# SAM9X60D1G_SOM register map
Vendor: Microchip Technology; Series: SAM9X6; File version: 0
Registers are 32-bit, read-write, reset 0x0 unless marked. A register's access mark holds for its fields unless they carry their own. Offsets are from the block's base; [hi:lo] are bit positions; {n}, {i} and the like mark numbered series; 'fields as' and 'values as' point back to an identical list.

## LCDC — LCD Controller
Base 0xF8038000
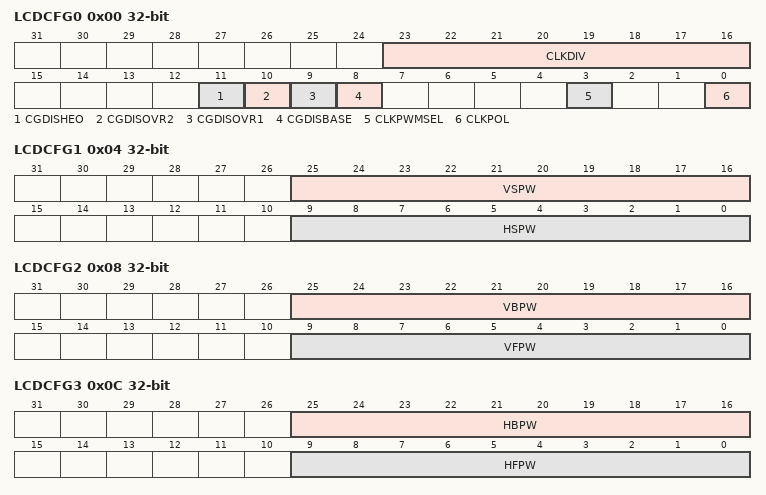
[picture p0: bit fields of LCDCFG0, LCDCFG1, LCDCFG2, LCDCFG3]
0x00 LCDCFG0 — LCD Controller Configuration Register 0
  [23:16] CLKDIV — LCD Controller Clock Divider
  [11] CGDISHEO — Clock Gating Disable Control for the High-End Overlay
  [10] CGDISOVR2 — Clock Gating Disable Control for the Overlay 2 Layer
  [9] CGDISOVR1 — Clock Gating Disable Control for the Overlay 1 Layer
  [8] CGDISBASE — Clock Gating Disable Control for the Base Layer
  [3] CLKPWMSEL — LCD Controller PWM Clock Source Selection
  [0] CLKPOL — LCD Controller Clock Polarity
0x04 LCDCFG1 — LCD Controller Configuration Register 1
  [25:16] VSPW — Vertical Synchronization Pulse Width
  [9:0] HSPW — Horizontal Synchronization Pulse Width
0x08 LCDCFG2 — LCD Controller Configuration Register 2
  [25:16] VBPW — Vertical Back Porch Width
  [9:0] VFPW — Vertical Front Porch Width
0x0C LCDCFG3 — LCD Controller Configuration Register 3
  [25:16] HBPW — Horizontal Back Porch Width
  [9:0] HFPW — Horizontal Front Porch Width
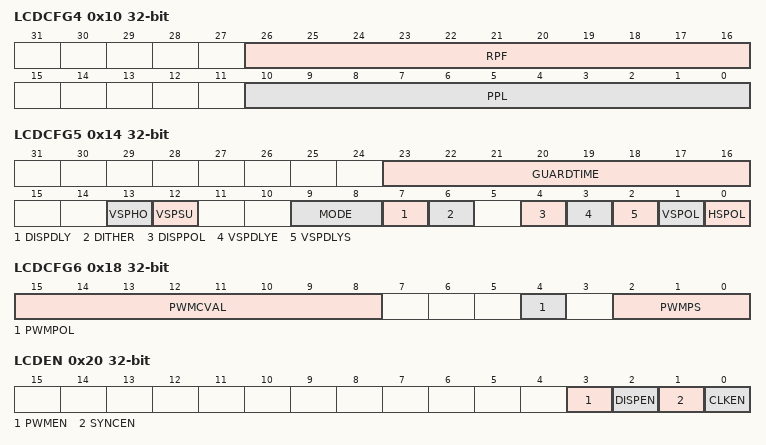
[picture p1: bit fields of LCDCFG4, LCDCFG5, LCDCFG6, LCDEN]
0x10 LCDCFG4 — LCD Controller Configuration Register 4
  [26:16] RPF — Number of Active Row Per Frame
  [10:0] PPL — Number of Pixels Per Line
0x14 LCDCFG5 — LCD Controller Configuration Register 5
  [23:16] GUARDTIME — LCD DISPLAY Guard Time
  [13] VSPHO — LCD Controller Vertical synchronization Pulse Hold Configuration
  [12] VSPSU — LCD Controller Vertical synchronization Pulse Setup Configuration
  [9:8] MODE — LCD Controller Output Mode
    0=OUTPUT_12BPP (LCD Output mode is set to 12 bits per pixel); 1=OUTPUT_16BPP (LCD Output mode is set to 16 bits per pixel); 2=OUTPUT_18BPP (LCD Output mode is set to 18 bits per pixel); 3=OUTPUT_24BPP (LCD Output mode is set to 24 bits per pixel)
  [7] DISPDLY — LCD Controller Display Power Signal Synchronization
  [6] DITHER — LCD Controller Dithering
  [4] DISPPOL — Display Signal Polarity
  [3] VSPDLYE — Vertical Synchronization Pulse End
  [2] VSPDLYS — Vertical Synchronization Pulse Start
  [1] VSPOL — Vertical Synchronization Pulse Polarity
  [0] HSPOL — Horizontal Synchronization Pulse Polarity
0x18 LCDCFG6 — LCD Controller Configuration Register 6
  [15:8] PWMCVAL — LCD Controller PWM Compare Value
  [4] PWMPOL — LCD Controller PWM Signal Polarity
  [2:0] PWMPS — PWM Clock Prescaler
    0=DIV_1 (The counter advances at a rate of fCOUNTER = fPWM_SELECTED_CLOCK); 1=DIV_2 (The counter advances at a rate of fCOUNTER = fPWM_SELECTED_CLOCK/2); 2=DIV_4 (The counter advances at a rate of fCOUNTER = fPWM_SELECTED_CLOCK/4); 3=DIV_8 (The counter advances at a rate of fCOUNTER = fPWM_SELECTED_CLOCK/8); 4=DIV_16 (The counter advances at a rate of fCOUNTER = fPWM_SELECTED_CLOCK/16); 5=DIV_32 (The counter advances at a of rate fCOUNTER = fPWM_SELECTED_CLOCK/32); 6=DIV_64 (The counter advances at a of rate fCOUNTER = fPWM_SELECTED_CLOCK/64)
0x1C LCDCFG7 — LCD Controller Configuration Register 7
  [10:0] ROW — Row Identifier For Row Interrupt Signal
0x20 LCDEN wo — LCD Controller Enable Register
  [3] PWMEN — LCD Controller Pulse Width Modulation Enable
  [2] DISPEN — LCD Controller DISP Signal Enable
  [1] SYNCEN — LCD Controller Horizontal and Vertical Synchronization Enable
  [0] CLKEN — LCD Controller Pixel Clock Enable
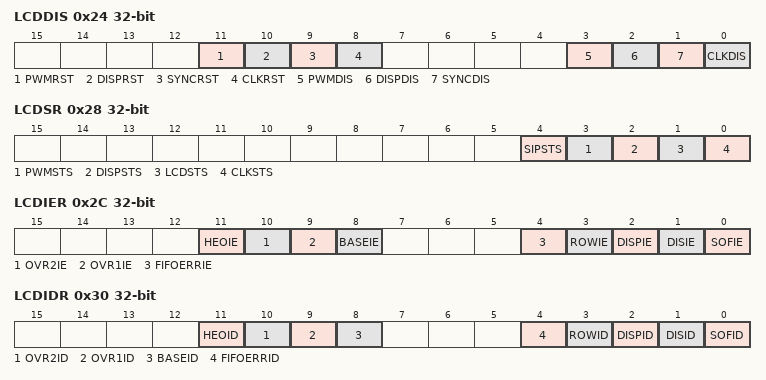
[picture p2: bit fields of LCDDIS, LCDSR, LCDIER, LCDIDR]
0x24 LCDDIS wo — LCD Controller Disable Register
  [11] PWMRST — LCD Controller PWM Reset
  [10] DISPRST — LCD Controller DISP Signal Reset
  [9] SYNCRST — LCD Controller Horizontal and Vertical Synchronization Reset
  [8] CLKRST — LCD Controller Clock Reset
  [3] PWMDIS — LCD Controller Pulse Width Modulation Disable
  [2] DISPDIS — LCD Controller DISP Signal Disable
  [1] SYNCDIS — LCD Controller Horizontal and Vertical Synchronization Disable
  [0] CLKDIS — LCD Controller Pixel Clock Disable
0x28 LCDSR ro — LCD Controller Status Register
  [4] SIPSTS — Synchronization In Progress
  [3] PWMSTS — LCD Controller PWM Signal Status
  [2] DISPSTS — LCD Controller DISP Signal Status
  [1] LCDSTS — LCD Controller Synchronization status
  [0] CLKSTS — Clock Status
0x2C LCDIER wo — LCD Controller Interrupt Enable Register
  [11] HEOIE — High-End Overlay Interrupt Enable
  [10] OVR2IE — Overlay 2 Interrupt Enable
  [9] OVR1IE — Overlay 1 Interrupt Enable
  [8] BASEIE — Base Layer Interrupt Enable
  [4] FIFOERRIE — Output FIFO Error Interrupt Enable
  [3] ROWIE — Row Interrupt Enable
  [2] DISPIE — Powerup/Powerdown Sequence Terminated Interrupt Enable
  [1] DISIE — LCD Disable Interrupt Enable
  [0] SOFIE — Start of Frame Interrupt Enable
0x30 LCDIDR wo — LCD Controller Interrupt Disable Register
  [11] HEOID — High-End Overlay Interrupt Disable
  [10] OVR2ID — Overlay 2 Interrupt Disable
  [9] OVR1ID — Overlay 1 Interrupt Disable
  [8] BASEID — Base Layer Interrupt Disable
  [4] FIFOERRID — Output FIFO Error Interrupt Disable
  [3] ROWID — Row Interrupt Disable
  [2] DISPID — Powerup/Powerdown Sequence Terminated Interrupt Disable
  [1] DISID — LCD Disable Interrupt Disable
  [0] SOFID — Start of Frame Interrupt Disable
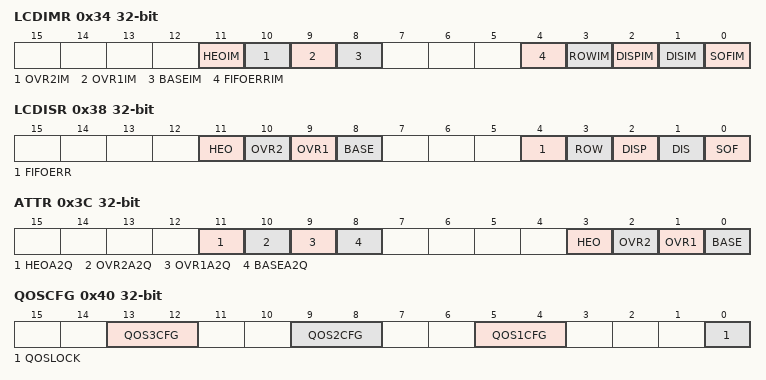
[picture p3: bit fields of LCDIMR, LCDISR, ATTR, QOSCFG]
0x34 LCDIMR ro — LCD Controller Interrupt Mask Register
  [11] HEOIM — High-End Overlay Interrupt Mask
  [10] OVR2IM — Overlay 2 Interrupt Mask
  [9] OVR1IM — Overlay 1 Interrupt Mask
  [8] BASEIM — Base Layer Interrupt Mask
  [4] FIFOERRIM — Output FIFO Error Interrupt Mask
  [3] ROWIM — Row Interrupt Mask
  [2] DISPIM — Powerup/Powerdown Sequence Terminated Interrupt Mask
  [1] DISIM — LCD Disable Interrupt Mask
  [0] SOFIM — Start of Frame Interrupt Mask
0x38 LCDISR ro — LCD Controller Interrupt Status Register
  [11] HEO — High-End Overlay Raw Interrupt Status
  [10] OVR2 — Overlay 2 Raw Interrupt Status
  [9] OVR1 — Overlay 1 Raw Interrupt Status
  [8] BASE — Base Layer Raw Interrupt Status
  [4] FIFOERR — Output FIFO Error
  [3] ROW — Row Interrupt Status
  [2] DISP — Powerup/Powerdown Sequence Terminated Interrupt Status
  [1] DIS — LCD Disable Interrupt Status
  [0] SOF — Start of Frame Interrupt Status
0x3C ATTR wo — LCD Controller Attribute Register
  [11] HEOA2Q — High-End Overlay Update Add To Queue
  [10] OVR2A2Q — Overlay 2 Update Add to Queue
  [9] OVR1A2Q — Overlay 1 Update Add To Queue
  [8] BASEA2Q — Base Layer Update Add To Queue
  [3] HEO — High-End Overlay Update Attribute
  [2] OVR2 — Overlay 2 Update Attribute
  [1] OVR1 — Overlay 1 Update Attribute
  [0] BASE — Base Layer Update Attribute
0x40 QOSCFG — LCD Controller QoS Configuration Register
  [13:12] QOS3CFG — Quality Of Service for 2 to 3 Transition
  [9:8] QOS2CFG — Quality Of Service for 1 to 2 Transition
  [5:4] QOS1CFG — Quality Of Service for 0 to 1 Transition
  [0] QOSLOCK — Quality Of Service Lock
{0x40+4i} QOS{i}M ro (i=1..3) — LCD Controller QoS {i} Metrics Register
  [19:0] MET{i} — Metrics QoS {i}
0x50 QOSMIN ro — LCD Controller QoS Min FIFO Level Register
  [8:0] LEVEL — Minimum FIFO Level
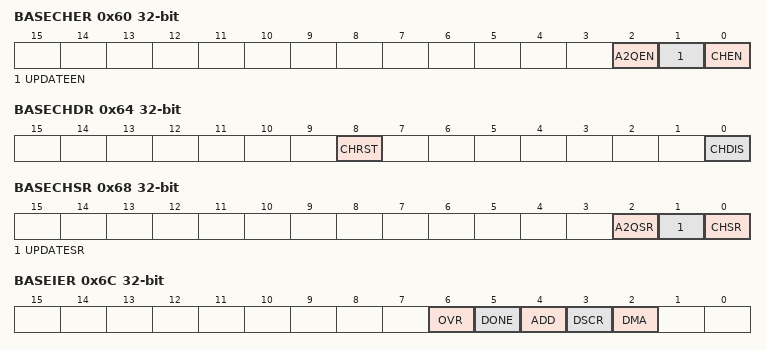
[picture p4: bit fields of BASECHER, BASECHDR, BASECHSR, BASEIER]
0x60 BASECHER wo — Base Layer Channel Enable Register
  [2] A2QEN — Add To Queue Enable
  [1] UPDATEEN — Update Overlay Attributes Enable
  [0] CHEN — Channel Enable
0x64 BASECHDR wo — Base Layer Channel Disable Register
  [8] CHRST — Channel Reset
  [0] CHDIS — Channel Disable
0x68 BASECHSR ro — Base Layer Channel Status Register
  [2] A2QSR — Add To Queue Status
  [1] UPDATESR — Update Overlay Attributes In Progress Status
  [0] CHSR — Channel Status
0x6C BASEIER wo — Base Layer Interrupt Enable Register
  [6] OVR — Overflow Interrupt Enable
  [5] DONE — End of List Interrupt Enable
  [4] ADD — Head Descriptor Loaded Interrupt Enable
  [3] DSCR — Descriptor Loaded Interrupt Enable
  [2] DMA — End of DMA Transfer Interrupt Enable
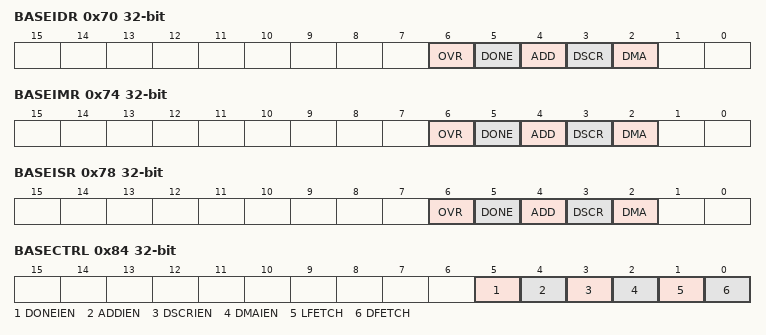
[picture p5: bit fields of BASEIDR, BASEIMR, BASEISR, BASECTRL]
0x70 BASEIDR wo — Base Layer Interrupt Disabled Register
  [6] OVR — Overflow Interrupt Disable
  [5] DONE — End of List Interrupt Disable
  [4] ADD — Head Descriptor Loaded Interrupt Disable
  [3] DSCR — Descriptor Loaded Interrupt Disable
  [2] DMA — End of DMA Transfer Interrupt Disable
0x74 BASEIMR ro — Base Layer Interrupt Mask Register
  [6] OVR — Overflow Interrupt Mask
  [5] DONE — End of List Interrupt Mask
  [4] ADD — Head Descriptor Loaded Interrupt Mask
  [3] DSCR — Descriptor Loaded Interrupt Mask
  [2] DMA — End of DMA Transfer Interrupt Mask
0x78 BASEISR ro — Base Layer Interrupt Status Register
  [6] OVR — Overflow Detected
  [5] DONE — End of List Detected
  [4] ADD — Head Descriptor Loaded
  [3] DSCR — DMA Descriptor Loaded
  [2] DMA — End of DMA Transfer
0x7C BASEHEAD — Base DMA Head Register
  [31:2] HEAD — DMA Head Pointer
0x80 BASEADDR — Base DMA Address Register
  [31:0] ADDR — DMA Transfer Start Address
0x84 BASECTRL — Base DMA Control Register
  [5] DONEIEN — End of List Interrupt Enable
  [4] ADDIEN — Add Head Descriptor to Queue Interrupt Enable
  [3] DSCRIEN — Descriptor Loaded Interrupt Enable
  [2] DMAIEN — End of DMA Transfer Interrupt Enable
  [1] LFETCH — Lookup Table Fetch Enable
  [0] DFETCH — Transfer Descriptor Fetch Enable
0x88 BASENEXT — Base DMA Next Register
  [31:0] NEXT — DMA Descriptor Next Address
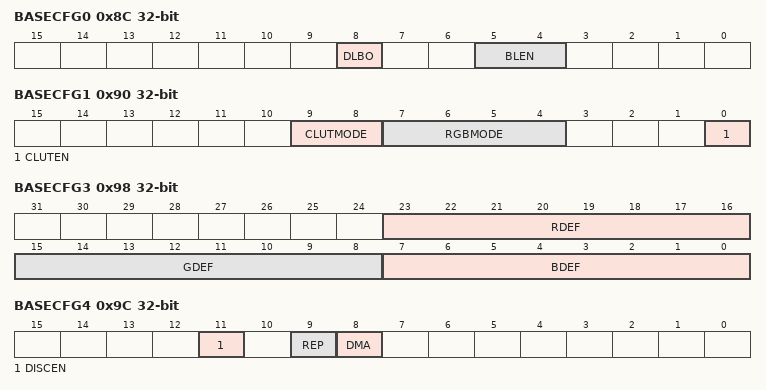
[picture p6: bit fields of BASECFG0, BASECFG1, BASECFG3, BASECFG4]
0x8C BASECFG0 — Base Layer Configuration Register 0
  [8] DLBO — defined length Burst Only For Channel Bus Transaction
  [5:4] BLEN — System Bus Burst Length
    0=AHB_SINGLE (System bus access is started as soon as there is enough space in the FIFO to store one data. SINGLE, INCR, INCR4, INCR8 and INCR16 bursts are used. INCR is used for a burst of 2 and 3 beats.); 1=AHB_INCR4 (System bus access is started as soon as there is enough space in the FIFO to store a total amount of 4 data. A system bus INCR4 Burst is used. SINGLE, INCR and INCR4 bursts are used. INCR is used for a burst of 2 and 3 beats.); 2=AHB_INCR8 (System bus access is started as soon as there is enough space in the FIFO to store a total amount of 8 data. A system bus INCR8 Burst is used. SINGLE, INCR, INCR4 and INCR8 bursts are used. INCR is used for a burst of 2 and 3 beats.); 3=AHB_INCR16 (System bus access is started as soon as there is enough space in the FIFO to store a total amount of 16 data. A system bus INCR16 Burst is used. SINGLE, INCR, INCR4, INCR8 and INCR16 bursts are used. INCR is used for a burst of 2 and 3 beats.)
0x90 BASECFG1 — Base Layer Configuration Register 1
  [9:8] CLUTMODE — Color Lookup Table Mode Input Selection
    0=CLUT_1BPP (Color Lookup Table mode set to 1 bit per pixel); 1=CLUT_2BPP (Color Lookup Table mode set to 2 bits per pixel); 2=CLUT_4BPP (Color Lookup Table mode set to 4 bits per pixel); 3=CLUT_8BPP (Color Lookup Table mode set to 8 bits per pixel)
  [7:4] RGBMODE — RGB Mode Input Selection
    0=_12BPP_RGB_444; 1=_16BPP_ARGB_4444; 2=_16BPP_RGBA_4444; 3=_16BPP_RGB_565; 4=_16BPP_TRGB_1555; 5=_18BPP_RGB_666; 6=_18BPP_RGB_666PACKED; 7=_19BPP_TRGB_1666; 8=_19BPP_TRGB_PACKED (19 bpp TRGB 1666 PACKED); 9=_24BPP_RGB_888; 10=_24BPP_RGB_888_PACKED; 11=_25BPP_TRGB_1888; 12=_32BPP_ARGB_8888; 13=_32BPP_RGBA_8888
  [0] CLUTEN — Color Lookup Table Mode Enable
0x94 BASECFG2 — Base Layer Configuration Register 2
  [31:0] XSTRIDE — Horizontal Stride
0x98 BASECFG3 — Base Layer Configuration Register 3
  [23:16] RDEF — Red Default
  [15:8] GDEF — Green Default
  [7:0] BDEF — Blue Default
0x9C BASECFG4 — Base Layer Configuration Register 4
  [11] DISCEN — Discard Area Enable
  [9] REP — Use Replication logic to expand RGB color to 24 bits
  [8] DMA — Use DMA Data Path
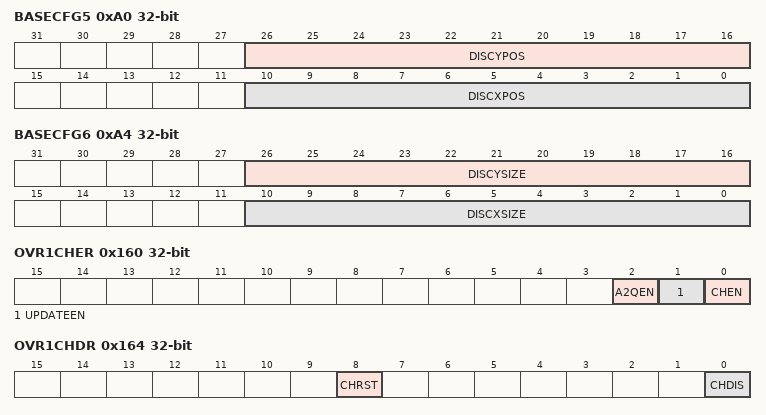
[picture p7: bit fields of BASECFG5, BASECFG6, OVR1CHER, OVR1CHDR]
0xA0 BASECFG5 — Base Layer Configuration Register 5
  [26:16] DISCYPOS — Discard Area Vertical Coordinate
  [10:0] DISCXPOS — Discard Area Horizontal Coordinate
0xA4 BASECFG6 — Base Layer Configuration Register 6
  [26:16] DISCYSIZE — Discard Area Vertical Size
  [10:0] DISCXSIZE — Discard Area Horizontal Size
0x160 OVR1CHER wo — Overlay 1 Channel Enable Register
  fields as BASECHER
0x164 OVR1CHDR wo — Overlay 1 Channel Disable Register
  [8] CHRST — Channel Reset
  [0] CHDIS — Channel Disable
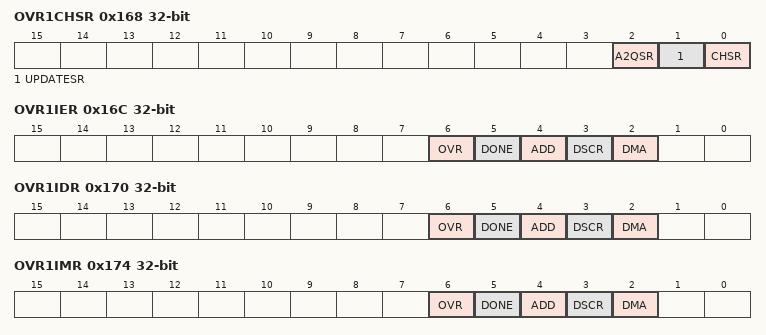
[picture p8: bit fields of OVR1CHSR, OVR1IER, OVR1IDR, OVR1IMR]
0x168 OVR1CHSR ro — Overlay 1 Channel Status Register
  fields as BASECHSR
0x16C OVR1IER wo — Overlay 1 Interrupt Enable Register
  fields as BASEIER
0x170 OVR1IDR wo — Overlay 1 Interrupt Disable Register
  fields as BASEIDR
0x174 OVR1IMR ro — Overlay 1 Interrupt Mask Register
  fields as BASEIMR
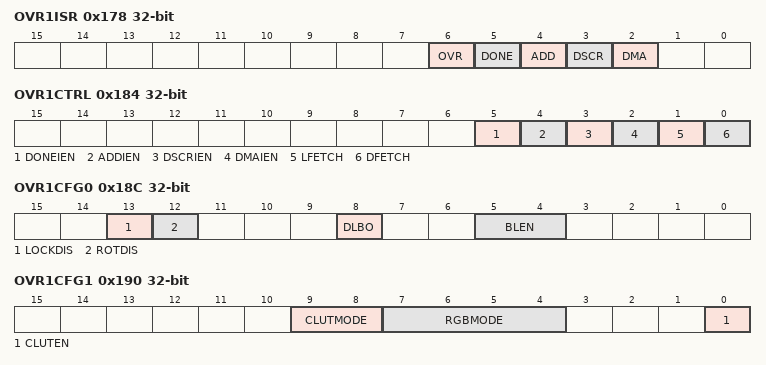
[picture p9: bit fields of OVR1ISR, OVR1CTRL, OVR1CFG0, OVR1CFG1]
0x178 OVR1ISR ro — Overlay 1 Interrupt Status Register
  fields as BASEISR
0x17C OVR1HEAD — Overlay 1 DMA Head Register
  [31:2] HEAD — DMA Head Pointer
0x180 OVR1ADDR — Overlay 1 DMA Address Register
  [31:0] ADDR — DMA Transfer Overlay 1 Address
0x184 OVR1CTRL — Overlay 1 DMA Control Register
  fields as BASECTRL
0x188 OVR1NEXT — Overlay 1 DMA Next Register
  [31:0] NEXT — DMA Descriptor Next Address
0x18C OVR1CFG0 — Overlay 1 Configuration Register 0
  [13] LOCKDIS — Hardware Rotation Lock Disable
  [12] ROTDIS — Hardware Rotation Optimization Disable
  [8] DLBO — defined length Burst Only for Channel Bus Transaction
  [5:4] BLEN — System Bus Burst Length
    0=AHB_BLEN_SINGLE (System bus access is started as soon as there is enough space in the FIFO to store one data. SINGLE, INCR, INCR4, INCR8 and INCR16 bursts are used. INCR is used for a burst of 2 and 3 beats.); 1=AHB_BLEN_INCR4 (System bus access is started as soon as there is enough space in the FIFO to store a total amount of 4 data. A system bus INCR4 Burst is used. SINGLE, INCR and INCR4 bursts are used. INCR is used for a burst of 2 and 3 beats.); 2=AHB_BLEN_INCR8 (System bus access is started as soon as there is enough space in the FIFO to store a total amount of 8 data. A system bus INCR8 Burst is used. SINGLE, INCR, INCR4 and INCR8 bursts are used. INCR is used for a burst of 2 and 3 beats.); 3=AHB_BLEN_INCR16 (System bus access is started as soon as there is enough space in the FIFO to store a total amount of 16 data. A system bus INCR16 Burst is used. SINGLE, INCR, INCR4, INCR8 and INCR16 bursts are used. INCR is used for a burst of 2 and 3 beats.)
0x190 OVR1CFG1 — Overlay 1 Configuration Register 1
  fields as BASECFG1
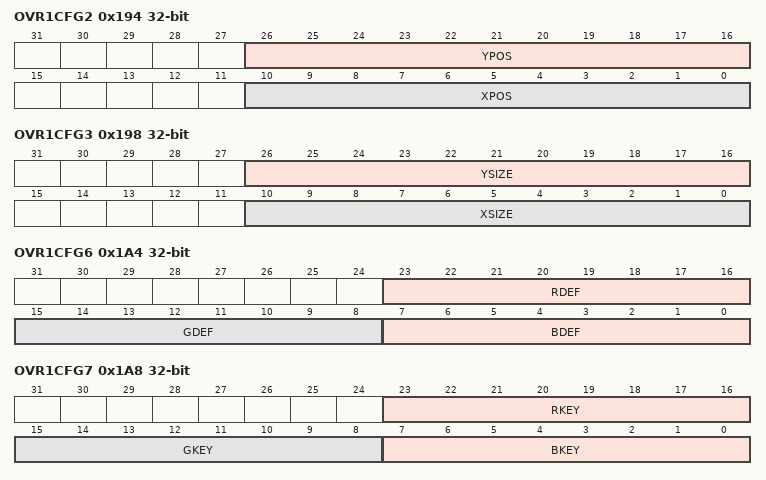
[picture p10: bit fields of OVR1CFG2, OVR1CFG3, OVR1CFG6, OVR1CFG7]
0x194 OVR1CFG2 — Overlay 1 Configuration Register 2
  [26:16] YPOS — Vertical Window Position
  [10:0] XPOS — Horizontal Window Position
0x198 OVR1CFG3 — Overlay 1 Configuration Register 3
  [26:16] YSIZE — Vertical Window Size
  [10:0] XSIZE — Horizontal Window Size
0x19C OVR1CFG4 — Overlay 1 Configuration Register 4
  [31:0] XSTRIDE — Horizontal Stride
0x1A0 OVR1CFG5 — Overlay 1 Configuration Register 5
  [31:0] PSTRIDE — Pixel Stride
0x1A4 OVR1CFG6 — Overlay 1 Configuration Register 6
  fields as BASECFG3
0x1A8 OVR1CFG7 — Overlay 1 Configuration Register 7
  [23:16] RKEY — Red Color Component Chroma Key
  [15:8] GKEY — Green Color Component Chroma Key
  [7:0] BKEY — Blue Color Component Chroma Key
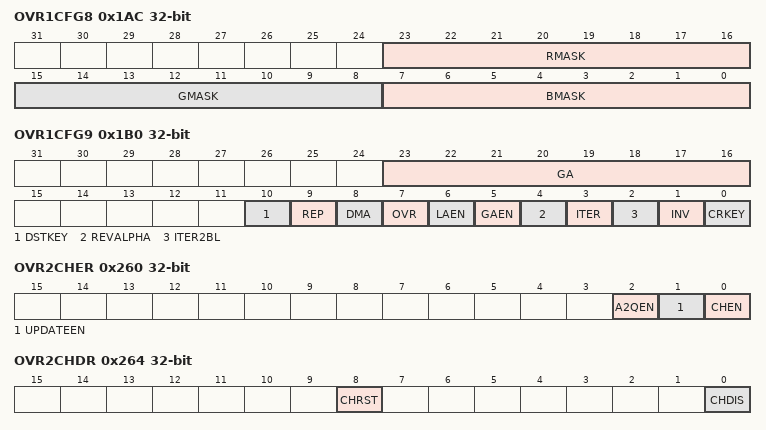
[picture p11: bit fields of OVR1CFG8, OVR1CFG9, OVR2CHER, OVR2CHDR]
0x1AC OVR1CFG8 — Overlay 1 Configuration Register 8
  [23:16] RMASK — Red Color Component Chroma Key Mask
  [15:8] GMASK — Green Color Component Chroma Key Mask
  [7:0] BMASK — Blue Color Component Chroma Key Mask
0x1B0 OVR1CFG9 — Overlay 1 Configuration Register 9
  [23:16] GA — Blender Global Alpha
  [10] DSTKEY — Destination Chroma Keying
  [9] REP — Use Replication logic to expand RGB color to 24 bits
  [8] DMA — Blender DMA Layer Enable
  [7] OVR — Blender Overlay Layer Enable
  [6] LAEN — Blender Local Alpha Enable
  [5] GAEN — Blender Global Alpha Enable
  [4] REVALPHA — Blender Reverse Alpha
  [3] ITER — Blender Use Iterated Color
  [2] ITER2BL — Blender Iterated Color Enable
  [1] INV — Blender Inverted Blender Output Enable
  [0] CRKEY — Blender Chroma Key Enable
0x260 OVR2CHER wo — Overlay 2 Channel Enable Register
  fields as BASECHER
0x264 OVR2CHDR wo — Overlay 2 Channel Disable Register
  [8] CHRST — Channel Reset
  [0] CHDIS — Channel Disable
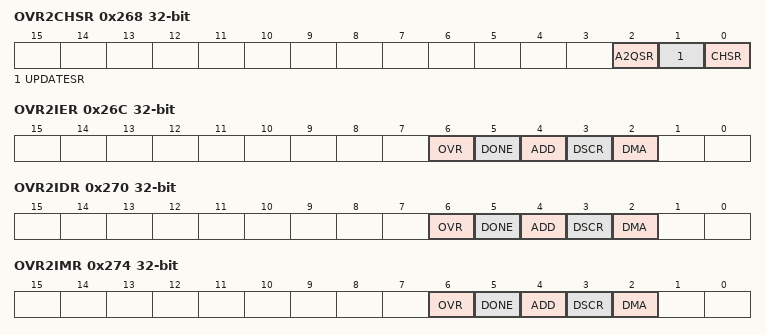
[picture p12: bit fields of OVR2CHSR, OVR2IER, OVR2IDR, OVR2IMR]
0x268 OVR2CHSR ro — Overlay 2 Channel Status Register
  fields as BASECHSR
0x26C OVR2IER wo — Overlay 2 Interrupt Enable Register
  fields as BASEIER
0x270 OVR2IDR wo — Overlay 2 Interrupt Disable Register
  fields as BASEIDR
0x274 OVR2IMR ro — Overlay 2 Interrupt Mask Register
  fields as BASEIMR
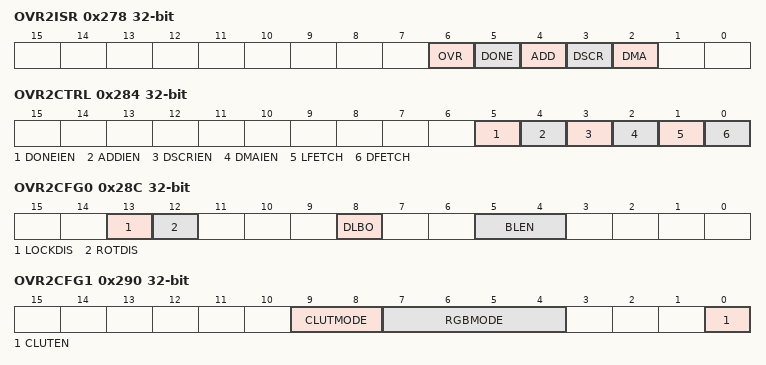
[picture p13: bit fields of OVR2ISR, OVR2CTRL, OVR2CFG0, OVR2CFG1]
0x278 OVR2ISR ro — Overlay 2 Interrupt Status Register
  fields as BASEISR
0x27C OVR2HEAD — Overlay 2 DMA Head Register
  [31:2] HEAD — DMA Head Pointer
0x280 OVR2ADDR — Overlay 2 DMA Address Register
  [31:0] ADDR — DMA Transfer Overlay 2 Address
0x284 OVR2CTRL — Overlay 2 DMA Control Register
  fields as BASECTRL
0x288 OVR2NEXT — Overlay 2 DMA Next Register
  [31:0] NEXT — DMA Descriptor Next Address
0x28C OVR2CFG0 — Overlay 2 Configuration Register 0
  [13] LOCKDIS — Hardware Rotation Lock Disable
  [12] ROTDIS — Hardware Rotation Optimization Disable
  [8] DLBO — Defined Length Burst Only For Channel Bus Transaction
  [5:4] BLEN — System Bus Burst Length
    values as BASECFG0.BLEN
0x290 OVR2CFG1 — Overlay 2 Configuration Register 1
  fields as BASECFG1
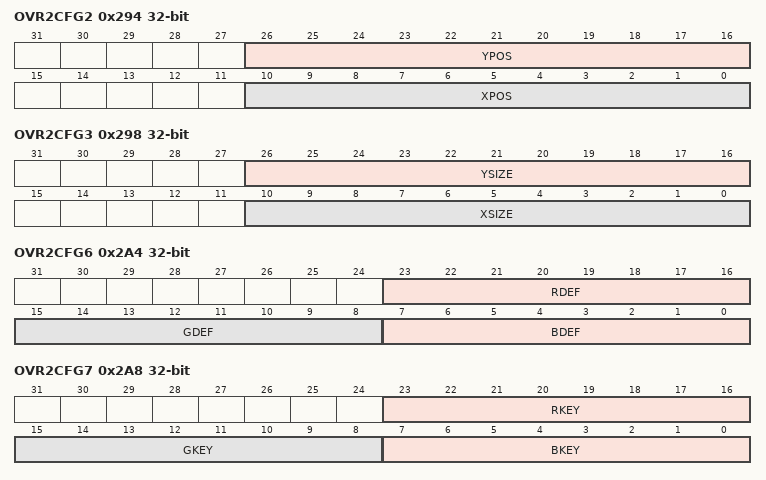
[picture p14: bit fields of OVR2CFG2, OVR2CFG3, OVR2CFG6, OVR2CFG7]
0x294 OVR2CFG2 — Overlay 2 Configuration Register 2
  fields as OVR1CFG2
0x298 OVR2CFG3 — Overlay 2 Configuration Register 3
  fields as OVR1CFG3
0x29C OVR2CFG4 — Overlay 2 Configuration Register 4
  [31:0] XSTRIDE — Horizontal Stride
0x2A0 OVR2CFG5 — Overlay 2 Configuration Register 5
  [31:0] PSTRIDE — Pixel Stride
0x2A4 OVR2CFG6 — Overlay 2 Configuration Register 6
  fields as BASECFG3
0x2A8 OVR2CFG7 — Overlay 2 Configuration Register 7
  fields as OVR1CFG7
0x2AC OVR2CFG8 — Overlay 2 Configuration Register 8
  fields as OVR1CFG8
0x2B0 OVR2CFG9 — Overlay 2 Configuration Register 9
  fields as OVR1CFG9
0x360 HEOCHER wo — High-End Overlay Channel Enable Register
  fields as BASECHER
0x364 HEOCHDR wo — High-End Overlay Channel Disable Register
  [8] CHRST — Channel Reset
  [0] CHDIS — Channel Disable
0x368 HEOCHSR ro — High-End Overlay Channel Status Register
  fields as BASECHSR
0x36C HEOIER wo — High-End Overlay Interrupt Enable Register
  [22] VOVR — Overflow for V Chrominance Interrupt Enable
  [21] VDONE — End of List for V Chrominance Interrupt Enable
  [20] VADD — Head Descriptor Loaded for V Chrominance Interrupt Enable
  [19] VDSCR — Descriptor Loaded for V Chrominance Interrupt Enable
  [18] VDMA — End of DMA for V Chrominance Transfer Interrupt Enable
  [14] UOVR — Overflow for U or UV Chrominance Interrupt Enable
  [13] UDONE — End of List for U or UV Chrominance Interrupt Enable
  [12] UADD — Head Descriptor Loaded for U or UV Chrominance Interrupt Enable
  [11] UDSCR — Descriptor Loaded for U or UV Chrominance Interrupt Enable
  [10] UDMA — End of DMA Transfer for U or UV Chrominance Interrupt Enable
  [6] OVR — Overflow Interrupt Enable
  [5] DONE — End of List Interrupt Enable
  [4] ADD — Head Descriptor Loaded Interrupt Enable
  [3] DSCR — Descriptor Loaded Interrupt Enable
  [2] DMA — End of DMA Transfer Interrupt Enable
0x370 HEOIDR wo — High-End Overlay Interrupt Disable Register
  [22] VOVR — Overflow for V Chrominance Component Interrupt Disable
  [21] VDONE — End of List for V Chrominance Component Interrupt Disable
  [20] VADD — Head Descriptor Loaded for V Chrominance Component Interrupt Disable
  [19] VDSCR — Descriptor Loaded for V Chrominance Component Interrupt Disable
  [18] VDMA — End of DMA Transfer for V Chrominance Component Interrupt Disable
  [14] UOVR — Overflow Interrupt for U or UV Chrominance Component Disable
  [13] UDONE — End of List Interrupt for U or UV Chrominance Component Disable
  [12] UADD — Head Descriptor Loaded for U or UV Chrominance Component Interrupt Disable
  [11] UDSCR — Descriptor Loaded for U or UV Chrominance Component Interrupt Disable
  [10] UDMA — End of DMA Transfer for U or UV Chrominance Component Interrupt Disable
  [6] OVR — Overflow Interrupt Disable
  [5] DONE — End of List Interrupt Disable
  [4] ADD — Head Descriptor Loaded Interrupt Disable
  [3] DSCR — Descriptor Loaded Interrupt Disable
  [2] DMA — End of DMA Transfer Interrupt Disable
0x374 HEOIMR ro — High-End Overlay Interrupt Mask Register
  [22] VOVR — Overflow for V Chrominance Interrupt Mask
  [21] VDONE — End of List for V Chrominance Component Mask
  [20] VADD — Head Descriptor Loaded for V Chrominance Component Mask
  [19] VDSCR — Descriptor Loaded for V Chrominance Component Interrupt Mask
  [18] VDMA — End of DMA Transfer for V Chrominance Component Interrupt Mask
  [14] UOVR — Overflow for U Chrominance Interrupt Mask
  [13] UDONE — End of List for U or UV Chrominance Component Mask
  [12] UADD — Head Descriptor Loaded for U or UV Chrominance Component Mask
  [11] UDSCR — Descriptor Loaded for U or UV Chrominance Component Interrupt Mask
  [10] UDMA — End of DMA Transfer for U or UV Chrominance Component Interrupt Mask
  [6] OVR — Overflow Interrupt Mask
  [5] DONE — End of List Interrupt Mask
  [4] ADD — Head Descriptor Loaded Interrupt Mask
  [3] DSCR — Descriptor Loaded Interrupt Mask
  [2] DMA — End of DMA Transfer Interrupt Mask
0x378 HEOISR ro — High-End Overlay Interrupt Status Register
  [22] VOVR — Overflow Detected for V Component
  [21] VDONE — End of List Detected for V Component
  [20] VADD — Head Descriptor Loaded for V Component
  [19] VDSCR — DMA Descriptor Loaded for V Component
  [18] VDMA — End of DMA Transfer for V Component
  [14] UOVR — Overflow Detected for U Component
  [13] UDONE — End of List Detected for U Component
  [12] UADD — Head Descriptor Loaded for U Component
  [11] UDSCR — DMA Descriptor Loaded for U Component
  [10] UDMA — End of DMA Transfer for U Component
  [6] OVR — Overflow Detected
  [5] DONE — End of List Detected
  [4] ADD — Head Descriptor Loaded
  [3] DSCR — DMA Descriptor Loaded
  [2] DMA — End of DMA Transfer
0x37C HEOHEAD — High-End Overlay DMA Head Register
  [31:2] HEAD — DMA Head Pointer
0x380 HEOADDR — High-End Overlay DMA Address Register
  [31:0] ADDR — DMA Transfer Start Address
0x384 HEOCTRL — High-End Overlay DMA Control Register
  fields as BASECTRL
0x388 HEONEXT — High-End Overlay DMA Next Register
  [31:0] NEXT — DMA Descriptor Next Address
0x38C HEOUHEAD — High-End Overlay U-UV DMA Head Register
  [31:0] UHEAD — DMA Head Pointer
0x390 HEOUADDR — High-End Overlay U-UV DMA Address Register
  [31:0] UADDR — DMA Transfer Start Address for U or UV Chrominance
0x394 HEOUCTRL — High-End Overlay U-UV DMA Control Register
  [5] UDONEIEN — End of List Interrupt Enable
  [4] UADDIEN — Add Head Descriptor to Queue Interrupt Enable
  [3] UDSCRIEN — Descriptor Loaded Interrupt Enable
  [2] UDMAIEN — End of DMA Transfer Interrupt Enable
  [0] UDFETCH — Transfer Descriptor Fetch Enable
0x398 HEOUNEXT — High-End Overlay U-UV DMA Next Register
  [31:0] UNEXT — DMA Descriptor Next Address
0x39C HEOVHEAD — High-End Overlay V DMA Head Register
  [31:0] VHEAD — DMA Head Pointer
0x3A0 HEOVADDR — High-End Overlay V DMA Address Register
  [31:0] VADDR — DMA Transfer Start Address for V Chrominance
0x3A4 HEOVCTRL — High-End Overlay V DMA Control Register
  [5] VDONEIEN — End of List Interrupt Enable
  [4] VADDIEN — Add Head Descriptor to Queue Interrupt Enable
  [3] VDSCRIEN — Descriptor Loaded Interrupt Enable
  [2] VDMAIEN — End of DMA Transfer Interrupt Enable
  [0] VDFETCH — Transfer Descriptor Fetch Enable
0x3A8 HEOVNEXT — High-End Overlay V DMA Next Register
  [31:0] VNEXT — DMA Descriptor Next Address
0x3AC HEOCFG0 — High-End Overlay Configuration Register 0
  [13] LOCKDIS — Hardware Rotation Lock Disable
  [12] ROTDIS — Hardware Rotation Optimization Disable
  [8] DLBO — Defined Length Burst Only For Channel Bus Transaction
  [7:6] BLENUV — System Bus Burst Length for U-V Channel
    values as BASECFG0.BLEN
  [5:4] BLEN — System Bus Burst Length
    values as OVR1CFG0.BLEN
0x3B0 HEOCFG1 — High-End Overlay Configuration Register 1
  [20] DSCALEOPT — Down Scaling Bandwidth Optimization
  [17] YUV422SWP — YUV 4:2:2 Swap
  [16] YUV422ROT — YUV 4:2:2 Rotation
  [15:12] YUVMODE — YUV Mode Input Selection
  [9:8] CLUTMODE — Color Lookup Table Mode Input Selection
    values as BASECFG1.CLUTMODE
  [7:4] RGBMODE — RGB Mode Input Selection
    values as BASECFG1.RGBMODE
  [1] YUVEN — YUV Color Space Enable
  [0] CLUTEN — Color Lookup Table Mode Enable
0x3B4 HEOCFG2 — High-End Overlay Configuration Register 2
  fields as OVR1CFG2
0x3B8 HEOCFG3 — High-End Overlay Configuration Register 3
  fields as OVR1CFG3
0x3BC HEOCFG4 — High-End Overlay Configuration Register 4
  [26:16] YMEMSIZE — Vertical image Size in Memory
  [10:0] XMEMSIZE — Horizontal image Size in Memory
0x3C0 HEOCFG5 — High-End Overlay Configuration Register 5
  [31:0] XSTRIDE — Horizontal Stride
0x3C4 HEOCFG6 — High-End Overlay Configuration Register 6
  [31:0] PSTRIDE — Pixel Stride
0x3C8 HEOCFG7 — High-End Overlay Configuration Register 7
  [31:0] UVXSTRIDE — UV Horizontal Stride
0x3CC HEOCFG8 — High-End Overlay Configuration Register 8
  [31:0] UVPSTRIDE — UV Pixel Stride
0x3D0 HEOCFG9 — High-End Overlay Configuration Register 9
  fields as BASECFG3
0x3D4 HEOCFG10 — High-End Overlay Configuration Register 10
  fields as OVR1CFG7
0x3D8 HEOCFG11 — High-End Overlay Configuration Register 11
  fields as OVR1CFG8
0x3DC HEOCFG12 — High-End Overlay Configuration Register 12
  [23:16] GA — Blender Global Alpha
  [12] VIDPRI — Video Priority
  [10] DSTKEY — Destination Chroma Keying
  [9] REP — Use Replication logic to expand RGB color to 24 bits
  [8] DMA — Blender DMA Layer Enable
  [7] OVR — Blender Overlay Layer Enable
  [6] LAEN — Blender Local Alpha Enable
  [5] GAEN — Blender Global Alpha Enable
  [4] REVALPHA — Blender Reverse Alpha
  [3] ITER — Blender Use Iterated Color
  [2] ITER2BL — Blender Iterated Color Enable
  [1] INV — Blender Inverted Blender Output Enable
  [0] CRKEY — Blender Chroma Key Enable
0x3E0 HEOCFG13 — High-End Overlay Configuration Register 13
  [31] SCALEN — Hardware Scaler Enable
  [29:16] YFACTOR — Vertical Scaling Factor
  [13:0] XFACTOR — Horizontal Scaling Factor
0x3E4 HEOCFG14 — High-End Overlay Configuration Register 14
  [30] CSCYOFF — Color Space Conversion Offset
  [29:20] CSCRV — Color Space Conversion V coefficient for Red Component 1:2:7 format
  [19:10] CSCRU — Color Space Conversion U coefficient for Red Component 1:2:7 format
  [9:0] CSCRY — Color Space Conversion Y coefficient for Red Component 1:2:7 format
0x3E8 HEOCFG15 — High-End Overlay Configuration Register 15
  [30] CSCUOFF — Color Space Conversion Offset
  [29:20] CSCGV — Color Space Conversion V coefficient for Green Component 1:2:7 format
  [19:10] CSCGU — Color Space Conversion U coefficient for Green Component 1:2:7 format
  [9:0] CSCGY — Color Space Conversion Y coefficient for Green Component 1:2:7 format
0x3EC HEOCFG16 — High-End Overlay Configuration Register 16
  [30] CSCVOFF — Color Space Conversion Offset
  [29:20] CSCBV — Color Space Conversion V coefficient for Blue Component 1:2:7 format
  [19:10] CSCBU — Color Space Conversion U coefficient for Blue Component 1:2:7 format
  [9:0] CSCBY — Color Space Conversion Y coefficient for Blue Component 1:2:7 format
0x3F0 HEOCFG17 — High-End Overlay Configuration Register 17
  [8n+7:8n] XPHI0COEFF{n} (n=0..3) — Horizontal Coefficient for phase 0 tap {n}
0x3F4 HEOCFG18 — High-End Overlay Configuration Register 18
  [7:0] XPHI0COEFF4 — Horizontal Coefficient for phase 0 tap 4
0x3F8 HEOCFG19 — High-End Overlay Configuration Register 19
  [8n+7:8n] XPHI1COEFF{n} (n=0..3) — Horizontal Coefficient for phase 1 tap {n}
0x3FC HEOCFG20 — High-End Overlay Configuration Register 20
  [7:0] XPHI1COEFF4 — Horizontal Coefficient for phase 1 tap 4
0x400 HEOCFG21 — High-End Overlay Configuration Register 21
  [8n+7:8n] XPHI2COEFF{n} (n=0..3) — Horizontal Coefficient for phase 2 tap {n}
0x404 HEOCFG22 — High-End Overlay Configuration Register 22
  [7:0] XPHI2COEFF4 — Horizontal Coefficient for phase 2 tap 4
0x408 HEOCFG23 — High-End Overlay Configuration Register 23
  [8n+7:8n] XPHI3COEFF{n} (n=0..3) — Horizontal Coefficient for phase 3 tap {n}
0x40C HEOCFG24 — High-End Overlay Configuration Register 24
  [7:0] XPHI3COEFF4 — Horizontal Coefficient for phase 3 tap 4
0x410 HEOCFG25 — High-End Overlay Configuration Register 25
  [8n+7:8n] XPHI4COEFF{n} (n=0..3) — Horizontal Coefficient for phase 4 tap {n}
0x414 HEOCFG26 — High-End Overlay Configuration Register 26
  [7:0] XPHI4COEFF4 — Horizontal Coefficient for phase 4 tap 4
0x418 HEOCFG27 — High-End Overlay Configuration Register 27
  [8n+7:8n] XPHI5COEFF{n} (n=0..3) — Horizontal Coefficient for phase 5 tap {n}
0x41C HEOCFG28 — High-End Overlay Configuration Register 28
  [7:0] XPHI5COEFF4 — Horizontal Coefficient for phase 5 tap 4
0x420 HEOCFG29 — High-End Overlay Configuration Register 29
  [8n+7:8n] XPHI6COEFF{n} (n=0..3) — Horizontal Coefficient for phase 6 tap {n}
0x424 HEOCFG30 — High-End Overlay Configuration Register 30
  [7:0] XPHI6COEFF4 — Horizontal Coefficient for phase 6 tap 4
0x428 HEOCFG31 — High-End Overlay Configuration Register 31
  [8n+7:8n] XPHI7COEFF{n} (n=0..3) — Horizontal Coefficient for phase 7 tap {n}
0x42C HEOCFG32 — High-End Overlay Configuration Register 32
  [7:0] XPHI7COEFF4 — Horizontal Coefficient for phase 7 tap 4
{0x3AC+4i} HEOCFG{i} (i=33..40) — High-End Overlay Configuration Register {i}
  [23:16] YPHI{i-33}COEFF2 — Vertical Coefficient for phase {i-33} tap 2
  [15:8] YPHI{i-33}COEFF1 — Vertical Coefficient for phase {i-33} tap 1
  [7:0] YPHI{i-33}COEFF0 — Vertical Coefficient for phase {i-33} tap 0
0x450 HEOCFG41 — High-End Overlay Configuration Register 41
  [18:16] YPHIDEF — Vertical Filter Phase Offset
  [2:0] XPHIDEF — Horizontal Filter Phase Offset
{0x600+4i} BASECLUT[{i}] (i=0..255)
  [23:16] RCLUT — Red Color Entry
  [15:8] GCLUT — Green Color Entry
  [7:0] BCLUT — Blue Color Entry
{0xA00+4i} OVR1CLUT[{i}] (i=0..255) — Overlay 1 CLUT Register
  [31:24] ACLUT — Alpha Color Entry
  [23:16] RCLUT — Red Color Entry
  [15:8] GCLUT — Green Color Entry
  [7:0] BCLUT — Blue Color Entry
{0xE00+4i} OVR2CLUT[{i}] (i=0..255) — Overlay 2 CLUT Register
  fields as OVR1CLUT[0]
{0x1200+4i} HEOCLUT[{i}] (i=0..255) — High-End Overlay CLUT Register
  fields as OVR1CLUT[0]
